# FM33G0XX register map
File version: 1.0
CPU: SC000 r1p0, little endian, no MPU, no FPU, 3 interrupt priority bits
Registers are 32-bit, read-write, reset 0x0 unless marked. A register's access mark holds for its fields unless they carry their own. Offsets are from the block's base; [hi:lo] are bit positions; {n}, {i} and the like mark numbered series.

## RCC — RESET AND CLOCK CONTROL UNIT
Base 0x40000200
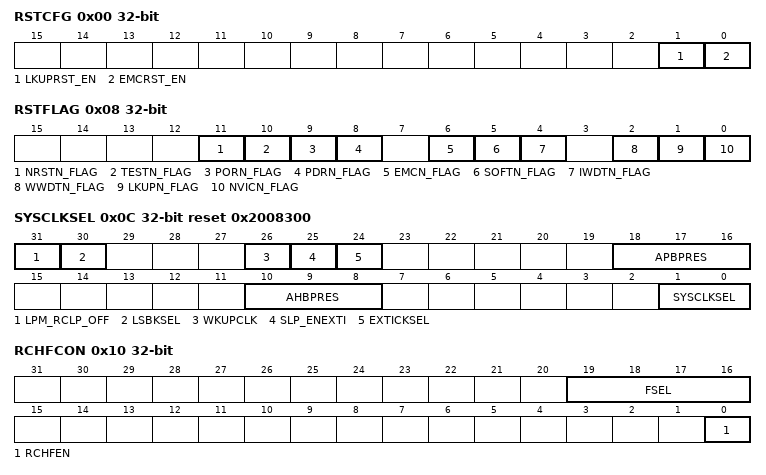
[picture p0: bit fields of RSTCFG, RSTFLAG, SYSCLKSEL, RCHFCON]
0x00 RSTCFG — RESET Config Register
  [1] LKUPRST_EN — LOCKUP reset enable
    0=DISABLE (LOCKUP reset is disable); 1=ENABLE (LOCKUP reset is enable)
  [0] EMCRST_EN — EMC reset enable
    0=DISABLE (EMC reset is disable); 1=ENABLE (EMC reset is enable)
0x04 SOFTRST — soft reset Register
  [31:0] SOFTRESET — Write softreset key word to reset CPU
0x08 RSTFLAG — RESET FLAG Register
  [11] NRSTN_FLAG — NRST reset flag
    0=NO_NRST (no NRST reset); 1=NRST (NRST reset occurs)
  [10] TESTN_FLAG — TEST reset flag
    0=NO_TEST (no TEST reset); 1=TEST (TEST reset occurs)
  [9] PORN_FLAG — POWER ON reset flag
    0=NO_POR (no POR reset); 1=POR (POR reset occurs)
  [8] PDRN_FLAG — POWER DOWN reset flag
    0=NO_PDR (no PDR reset); 1=PDR (PDR reset occurs)
  [6] EMCN_FLAG — EMC reset flag
    0=NO_EMC (no EMC reset); 1=EMC (EMC reset occurs)
  [5] SOFTN_FLAG — SOFT reset flag
    0=NO_SOFT (no SOFT reset); 1=SOFT (SOFT reset occurs)
  [4] IWDTN_FLAG — IWDT reset flag
    0=NO_IWDT (no IWDT reset); 1=IWDT (IWDT reset occurs)
  [2] WWDTN_FLAG — WWDT reset flag
    0=NO_WWDT (no WWDT reset); 1=WWDT (WWDT reset occurs)
  [1] LKUPN_FLAG — LOCKUP reset flag
    0=NO_LUCKUP (no LUCKUP reset); 1=LUCKUP (LUCKUP reset occurs)
  [0] NVICN_FLAG — NVIC reset flag
    0=NO_NVIC (no NVIC reset); 1=NVIC (NVIC reset occurs)
0x0C SYSCLKSEL reset 0x2008300 — system clock select Register
  [31] LPM_RCLP_OFF — RCLP enable bit at Sleep/Stop mode (only at crystless mode)
    0=ENABLE (Keep RCLP on at sleep/stop mode); 1=DISABLE (close RCLP at sleep/stop mode)
  [30] LSBKSEL — LSCLK CLK SOURCE SELECT (only at crystless mode)
    0=RCLP; 1=RCLF
  [26] WKUPCLK — wakeup clk select
    0=8MHz (running at 8MHz after wakeup); 1=512KHz (running at 512KHz after wakeup)
  [25] SLP_ENEXTI — EXTI sample clk enable bit ,at sleep/deepsleep mode
    0=DISABLE (EXTI sample clk disable); 1=ENABLE (EXTI sample clk enable)
  [24] EXTICKSEL — EXTI clk select
    0=AHBCLK (EXTI sample clk selects AHBCLK); 1=LSCLK (EXTI sample clk selects LSCLK)
  [18:16] APBPRES — APB clk divide
    {v}=NO_DIV (APB clock is not divided at 0x0xx) (v=0..3); 4=DIV2 (APB clock is divided by 2); 5=DIV4 (APB clock is divided by 4); 6=DIV8 (AHB clock is divided by 8); 7=DIV16 (AHB clock is divided by 16)
  [10:8] AHBPRES — AHB clk divide
    {v}=NO_DIV (AHB clock is not divided at 0x0xx) (v=0..3); 4=DIV2 (AHB clock is divided by 2); 5=DIV4 (AHB clock is divided by 4); 6=DIV8 (AHB clock is divided by 8); 7=DIV16 (AHB clock is divided by 16)
  [1:0] SYSCLKSEL — System clock select bit
    0=RCHF (system clock source is RCHF); 1=RCLF (system clock source is RCLF); 2=LSCLK (system clock source is LSCLK); 3=PLL (system clock source is PLL)
0x10 RCHFCON — RCHF config Register
  [19:16] FSEL — RCHF frequency select
    0=8MHz (RCHF center frequency is 8MHz); 1=16MHz (RCHF center frequency is 16MHz); 2=24MHz (RCHF center frequency is 24MHz); 15=36MHz (RCHF center frequency is 36MHz)
  [0] RCHFEN — RCHF enable bit
    0=DISABLE (RCHF is disable); 1=ENABLE (RCHF is enable)
0x14 RCHFTRIM reset 0x40
  [6:0] RCHFTRIM — RCHF trim bit
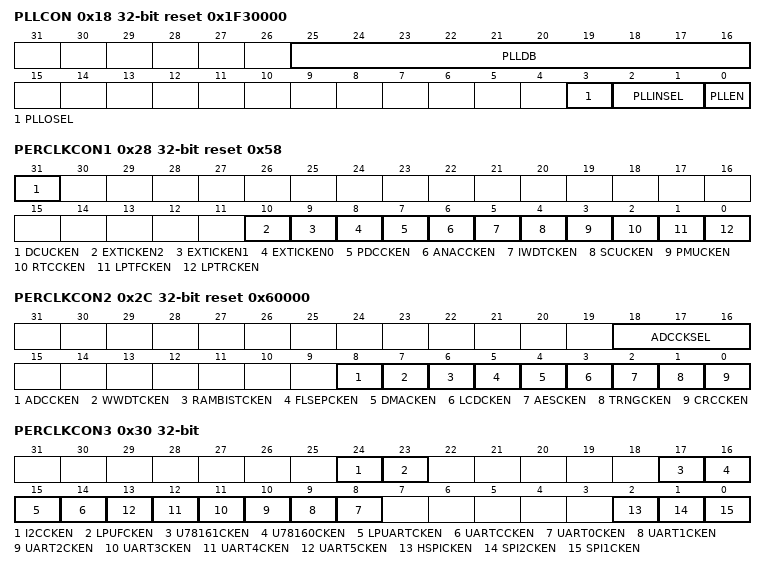
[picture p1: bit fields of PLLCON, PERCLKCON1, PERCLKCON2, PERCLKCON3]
0x18 PLLCON reset 0x1F30000 — PLL Config Register
  [25:16] PLLDB
  [3] PLLOSEL — PLL output select
    0=VCO/2 (PLL output is VCO/2); 1=VCO (PLL output is VCO)
  [2:1] PLLINSEL — PLL input clk source select
    0=XTLF (PLL input clk source is XTLF); 1=RCLP (PLL input clk source is RCLP); 2=RCHF/256 (PLL input clk source is RCHF/256); 3=XTLF (PLL input clk source is XTLF)
  [0] PLLEN — PLL enable bit
    0=DISABLE (PLL is disable); 1=ENABLE (PLL is enable)
0x1C RCLPCON — RCLP config Register
  [0] RCLP_EN_B — RCLP enable bit
    0=ENABLE (RCLP is enable); 1=DISABLE (RCLP is disable)
0x20 RCLPTRIM reset 0x8
  [3:0] RCLPTRIM — RCLP TRIM bit
0x24 XTLFIPW — XTLF IPW Config Register
  [2:0] XTLFIPW — XTLF IPW bit
    0=450 nA (XTLF IPW is 450 nA); 1=400 nA (XTLF IPW is 400 nA); 2=350 nA (XTLF IPW is 350 nA); 3=300 nA (XTLF IPW is 300 nA); 4=250 nA (XTLF IPW is 250 nA); 5=200 nA (XTLF IPW is 200 nA); 6=150 nA (XTLF IPW is 150 nA); 7=100 nA (XTLF IPW is 100 nA)
0x28 PERCLKCON1 reset 0x58 — peripheral clk Config Register 1
  [31] DCUCKEN — DCU clk enable
    0=DISABLE (DCU clk is disable); 1=ENABLE (DCU clk is enable)
  [10] EXTICKEN2 — EXTI2 sample clk enable
    0=DISABLE (EXTI2 sample clk is disable); 1=ENABLE (EXTI2 sample clk is enable)
  [9] EXTICKEN1 — EXTI1 sample clk enable
    0=DISABLE (EXTI1 sample clk is disable); 1=ENABLE (EXTI1 sample clk is enable)
  [8] EXTICKEN0 — EXTI0 sample clk enable
    0=DISABLE (EXTI0 sample clk is disable); 1=ENABLE (EXTI0 sample clk is enable)
  [7] PDCCKEN — PDC clk enable
    0=DISABLE (PDC clk is disable); 1=ENABLE (PDC clk is enable)
  [6] ANACCKEN — ANAC clk enable
    0=DISABLE (ANAC clk is disable); 1=ENABLE (ANAC clk is enable)
  [5] IWDTCKEN — IWDT clk enable
    0=DISABLE (IWDT clk is disable); 1=ENABLE (IWDT clk is enable)
  [4] SCUCKEN — SCU clk enable
    0=DISABLE (SCU clk is disable); 1=ENABLE (SCU clk is enable)
  [3] PMUCKEN — PMU clk enable
    0=DISABLE (PMU clk is disable); 1=ENABLE (PMU clk is enable)
  [2] RTCCKEN — RTC clk enable
    0=DISABLE (RTC clk is disable); 1=ENABLE (RTC clk is enable)
  [1] LPTFCKEN — LPTIM function clk enable
    0=DISABLE (LPTIM function clk is disable); 1=ENABLE (LPTIM function clk is enable)
  [0] LPTRCKEN — LPTIM reg clk enable
    0=DISABLE (LPTIM reg clk is disable); 1=ENABLE (LPTIM reg clk is enable)
0x2C PERCLKCON2 reset 0x60000 — peripheral clk Config Register 2
  [18:16] ADCCKSEL — ADC clk select
    0=RCLF (ADC clk is RCLF); 1=RCHF/32 (ADC clk is RCHF/32); 2=RCHF/16 (ADC clk is RCHF/16); 3=RCHF/8 (ADC clk is RCHF/8); 4=RCHF/16 (ADC clk is RCHF/16); 5=RCLF (ADC clk is RCLF); 6=RCLF (ADC clk is RCLF); 7=RCLF (ADC clk is RCLF)
  [8] ADCCKEN — ADC clk enable
    0=DISABLE (ADC clk is disable); 1=ENABLE (ADC clk is enable)
  [7] WWDTCKEN — WWDT clk enable
    0=DISABLE (WWDT clk is disable); 1=ENABLE (WWDT clk is enable)
  [6] RAMBISTCKEN — RAMBIST clk enable
    0=DISABLE (RAMBIST clk is disable); 1=ENABLE (RAMBIST clk is enable)
  [5] FLSEPCKEN — NVMIF clk enable
    0=DISABLE (NVMIF clk is disable); 1=ENABLE (NVMIF clk is enable)
  [4] DMACKEN — DMA clk enable
    0=DISABLE (DMA clk is disable); 1=ENABLE (DMA clk is enable)
  [3] LCDCKEN — LCD clk enable
    0=DISABLE (LCD clk is disable); 1=ENABLE (LCD clk is enable)
  [2] AESCKEN — AES clk enable
    0=DISABLE (AES clk is disable); 1=ENABLE (AES clk is enable)
  [1] TRNGCKEN — RNG clk enable
    0=DISABLE (RNG clk is disable); 1=ENABLE (RNG clk is enable)
  [0] CRCCKEN — CRC clk enable
    0=DISABLE (CRC clk is disable); 1=ENABLE (CRC clk is enable)
0x30 PERCLKCON3 — peripheral clk Config Register 3
  [24] I2CCKEN — I2C clk enable
    0=DISABLE (I2C clk is disable); 1=ENABLE (I2C clk is enable)
  [23] LPUFCKEN — LPUART fuc clk select
    0=DISABLE (LPUART fuc clk is disable); 1=ENABLE (LPUART fuc clk is enable)
  [17] U78161CKEN — U78161 clk enable
    0=DISABLE (U78161 clk is disable); 1=ENABLE (U78161 clk is enable)
  [16] U78160CKEN — U78160 clk enable
    0=DISABLE (U78160 clk is disable); 1=ENABLE (U78160 clk is enable)
  [15] LPUARTCKEN — LPUART clk select
    0=DISABLE (LPUART clk is disable); 1=ENABLE (LPUART clk is enable)
  [14] UARTCCKEN — UART REG clk select
    0=DISABLE (UART reg clk is disable); 1=ENABLE (UART reg clk is enable)
  [n+8] UART{n}CKEN (n=0..5) — UART{n} clk enable
    0=DISABLE (UART{n} clk is disable); 1=ENABLE (UART{n} clk is enable)
  [2] HSPICKEN — HSPI clk enable
    0=DISABLE (HSPI clk is disable); 1=ENABLE (HSPI clk is enable)
  [1] SPI2CKEN — SPI2 clk enable
    0=DISABLE (SPI2 clk is disable); 1=ENABLE (SPI2 clk is enable)
  [0] SPI1CKEN — SPI1 clk enable
    0=DISABLE (SPI clk is disable); 1=ENABLE (SPI clk is enable)
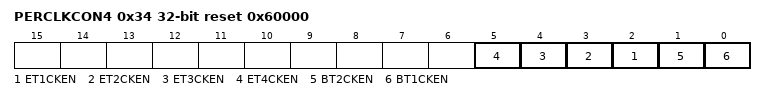
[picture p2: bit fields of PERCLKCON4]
0x34 PERCLKCON4 reset 0x60000 — peripheral clk Config Register 4
  [n+1] ET{n}CKEN (n=1..4) — ETimer{n} clk enable
    0=DISABLE (ET{n} clk is disable); 1=ENABLE (ET{n} clk is enable)
  [1] BT2CKEN — BaseTimer2 clk enable
    0=DISABLE (BT2 clk is disable); 1=ENABLE (BT2 clk is enable)
  [0] BT1CKEN — BaseTimer1 clk enable
    0=DISABLE (BT1 clk is disable); 1=ENABLE (BT1 clk is enable)
0x44 MPRIL — AHB master priority
  [0] MPRIL
    0=DMA (DMA is high priority); 1=CPU (CPU is high priority)
0x48 RCLFCON — RCLF config Register
  [0] RCLF_EN_B — RCLF enable bit
    0=ENABLE (RCLF is enable); 1=DISABLE (RCLF is disable)
0x4C RCLFTRIM reset 0x8
  [5:0] RCLFTRIM — RCLF TRIM bit
